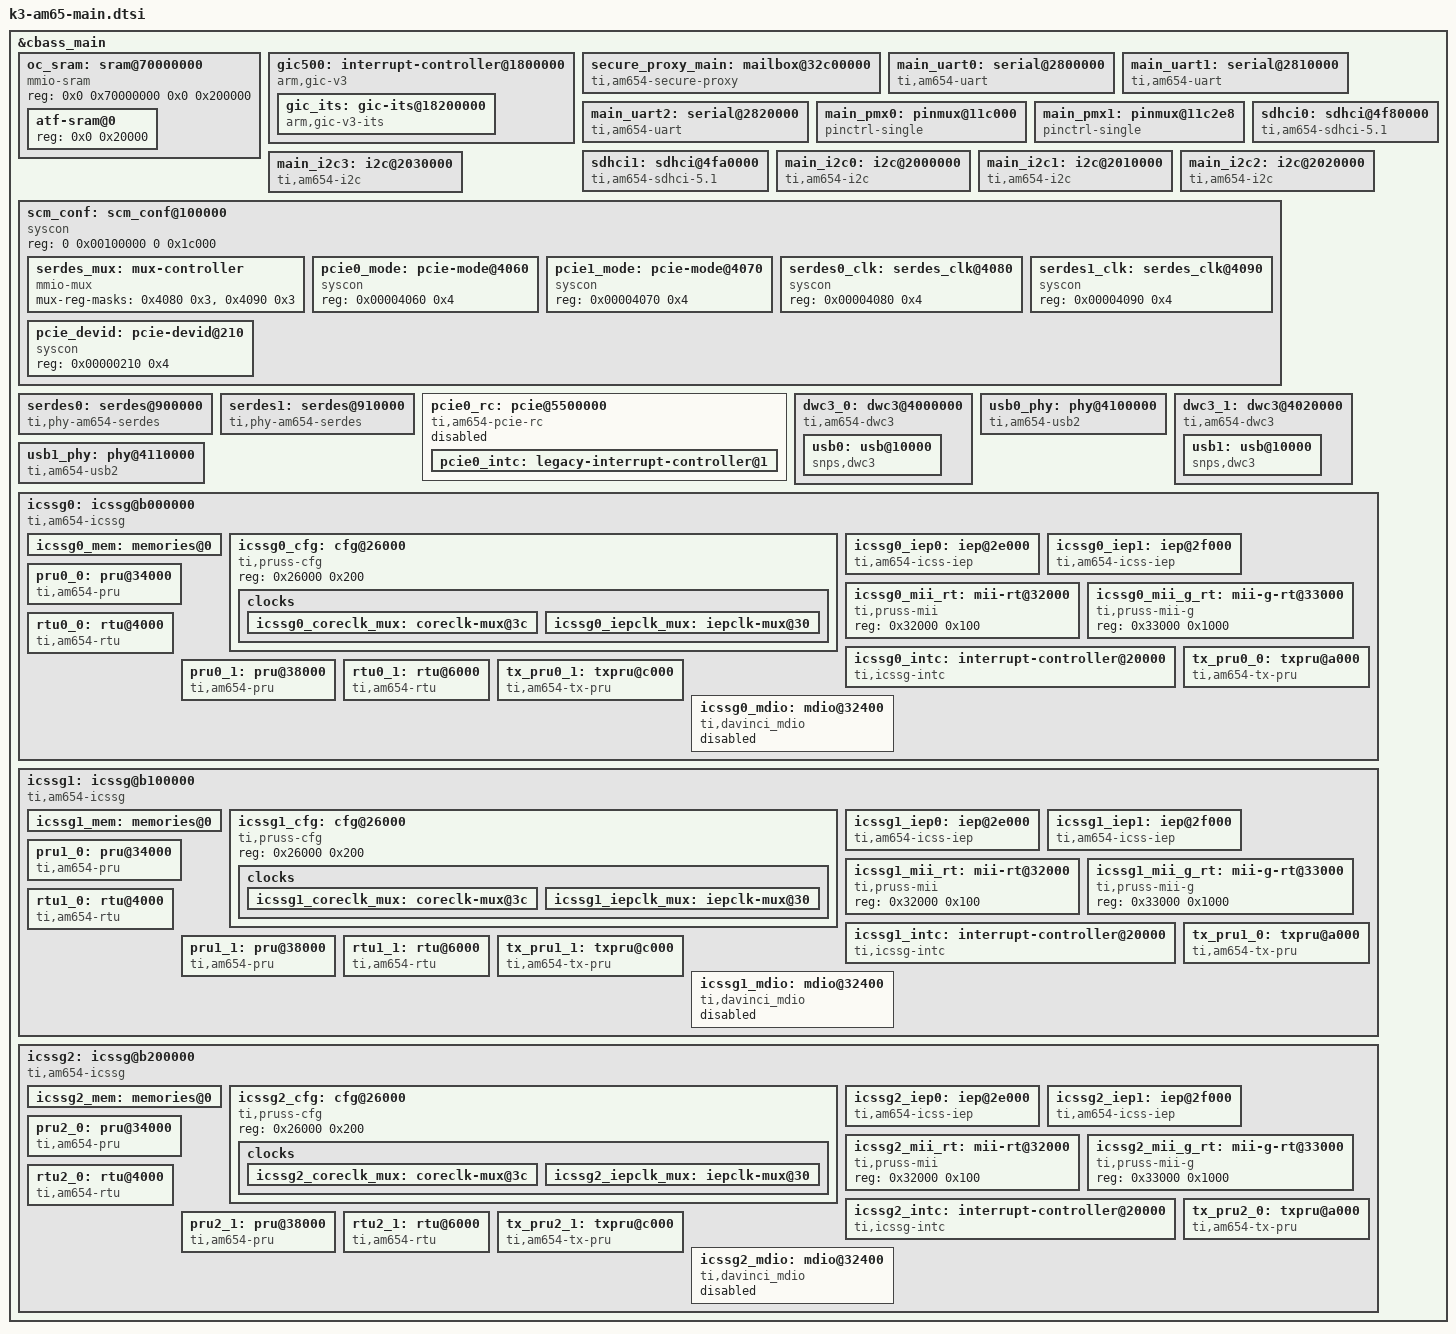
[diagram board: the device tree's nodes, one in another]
// SPDX-License-Identifier: GPL-2.0
/*
 * Device Tree Source for AM6 SoC Family Main Domain peripherals
 *
 * Copyright (C) 2016-2018 Texas Instruments Incorporated - http://www.ti.com/
 */

#include <dt-bindings/phy/phy-am654-serdes.h>
#include <dt-bindings/phy/phy.h>

&cbass_main {
	oc_sram: sram@70000000 {
		compatible = "mmio-sram";
		reg = <0x0 0x70000000 0x0 0x200000>;
		#address-cells = <1>;
		#size-cells = <1>;
		ranges = <0x0 0x0 0x70000000 0x200000>;

		atf-sram@0 {
			reg = <0x0 0x20000>;
		};
	};

	gic500: interrupt-controller@1800000 {
		compatible = "arm,gic-v3";
		#address-cells = <2>;
		#size-cells = <2>;
		ranges;
		#interrupt-cells = <3>;
		interrupt-controller;
		reg = <0x00 0x01800000 0x00 0x10000>,	/* GICD */
		      <0x00 0x01880000 0x00 0x90000>;	/* GICR */
		/*
		 * vcpumntirq:
		 * virtual CPU interface maintenance interrupt
		 */
		interrupts = <GIC_PPI 9 IRQ_TYPE_LEVEL_HIGH>;

		gic_its: gic-its@18200000 {
			compatible = "arm,gic-v3-its";
			reg = <0x00 0x01820000 0x00 0x10000>;
			msi-controller;
			#msi-cells = <1>;
		};
	};

	secure_proxy_main: mailbox@32c00000 {
		compatible = "ti,am654-secure-proxy";
		#mbox-cells = <1>;
		reg-names = "target_data", "rt", "scfg";
		reg = <0x00 0x32c00000 0x00 0x100000>,
		      <0x00 0x32400000 0x00 0x100000>,
		      <0x00 0x32800000 0x00 0x100000>;
		interrupt-names = "rx_011";
		interrupts = <GIC_SPI 37 IRQ_TYPE_LEVEL_HIGH>;
	};

	main_uart0: serial@2800000 {
		compatible = "ti,am654-uart";
		reg = <0x00 0x02800000 0x00 0x100>;
		reg-shift = <2>;
		reg-io-width = <4>;
		interrupts = <GIC_SPI 192 IRQ_TYPE_LEVEL_HIGH>;
		clock-frequency = <48000000>;
		current-speed = <115200>;
	};

	main_uart1: serial@2810000 {
		compatible = "ti,am654-uart";
		reg = <0x00 0x02810000 0x00 0x100>;
		reg-shift = <2>;
		reg-io-width = <4>;
		interrupts = <GIC_SPI 193 IRQ_TYPE_LEVEL_HIGH>;
		clock-frequency = <48000000>;
		current-speed = <115200>;
	};

	main_uart2: serial@2820000 {
		compatible = "ti,am654-uart";
		reg = <0x00 0x02820000 0x00 0x100>;
		reg-shift = <2>;
		reg-io-width = <4>;
		interrupts = <GIC_SPI 194 IRQ_TYPE_LEVEL_HIGH>;
		clock-frequency = <48000000>;
		current-speed = <115200>;
	};

	main_pmx0: pinmux@11c000 {
		compatible = "pinctrl-single";
		reg = <0x0 0x11c000 0x0 0x2e4>;
		#pinctrl-cells = <1>;
		pinctrl-single,register-width = <32>;
		pinctrl-single,function-mask = <0xffffffff>;
	};

	main_pmx1: pinmux@11c2e8 {
		compatible = "pinctrl-single";
		reg = <0x0 0x11c2e8 0x0 0x24>;
		#pinctrl-cells = <1>;
		pinctrl-single,register-width = <32>;
		pinctrl-single,function-mask = <0xffffffff>;
	};

	sdhci0: sdhci@4f80000 {
		compatible = "ti,am654-sdhci-5.1";
		reg = <0x0 0x4f80000 0x0 0x260>, <0x0 0x4f90000 0x0 0x134>;
		power-domains = <&k3_pds 47 TI_SCI_PD_EXCLUSIVE>;
		clocks = <&k3_clks 47 0>, <&k3_clks 47 1>;
		clock-names = "clk_ahb", "clk_xin";
		interrupts = <GIC_SPI 136 IRQ_TYPE_LEVEL_HIGH>;
		mmc-ddr-1_8v;
		mmc-hs200-1_8v;
		ti,otap-del-sel-legacy = <0x0>;
		ti,otap-del-sel-mmc-hs = <0x0>;
		ti,otap-del-sel-sd-hs = <0x0>;
		ti,otap-del-sel-sdr12 = <0x0>;
		ti,otap-del-sel-sdr25 = <0x0>;
		ti,otap-del-sel-sdr50 = <0x8>;
		ti,otap-del-sel-sdr104 = <0x5>;
		ti,otap-del-sel-ddr50 = <0x5>;
		ti,otap-del-sel-ddr52 = <0x5>;
		ti,otap-del-sel-hs200 = <0x5>;
		ti,otap-del-sel-hs400 = <0x0>;
		ti,itap-del-sel-legacy = <0xa>;
		ti,itap-del-sel-mmc-hs = <0x1>;
		ti,itap-del-sel-sdr12 = <0xa>;
		ti,itap-del-sel-sdr25 = <0x1>;
		ti,clkbuf-sel = <0x7>;
		ti,trm-icp = <0x8>;
		dma-coherent;
	};

	sdhci1: sdhci@4fa0000 {
		compatible = "ti,am654-sdhci-5.1";
		reg = <0x0 0x4fa0000 0x0 0x260>, <0x0 0x4fb0000 0x0 0x134>;
		power-domains = <&k3_pds 48 TI_SCI_PD_EXCLUSIVE>;
		clocks = <&k3_clks 48 0>, <&k3_clks 48 1>;
		clock-names = "clk_ahb", "clk_xin";
		interrupts = <GIC_SPI 137 IRQ_TYPE_LEVEL_HIGH>;
		ti,otap-del-sel-legacy = <0x0>;
		ti,otap-del-sel-mmc-hs = <0x0>;
		ti,otap-del-sel-sd-hs = <0x0>;
		ti,otap-del-sel-sdr12 = <0x0>;
		ti,otap-del-sel-sdr25 = <0x0>;
		ti,otap-del-sel-sdr50 = <0x8>;
		ti,otap-del-sel-sdr104 = <0x7>;
		ti,otap-del-sel-ddr50 = <0x4>;
		ti,otap-del-sel-ddr52 = <0x4>;
		ti,otap-del-sel-hs200 = <0x7>;
		ti,itap-del-sel-legacy = <0xa>;
		ti,itap-del-sel-mmc-hs = <0x1>;
		ti,itap-del-sel-sdr12 = <0xa>;
		ti,itap-del-sel-sdr25 = <0x1>;
		ti,clkbuf-sel = <0x7>;
		ti,trm-icp = <0x8>;
		dma-coherent;
	};

	main_i2c0: i2c@2000000 {
		compatible = "ti,am654-i2c", "ti,omap4-i2c";
		reg = <0x0 0x2000000 0x0 0x100>;
		interrupts = <GIC_SPI 200 IRQ_TYPE_LEVEL_HIGH>;
		#address-cells = <1>;
		#size-cells = <0>;
		clock-names = "fck";
		clocks = <&k3_clks 110 1>;
		power-domains = <&k3_pds 110 TI_SCI_PD_EXCLUSIVE>;
	};

	main_i2c1: i2c@2010000 {
		compatible = "ti,am654-i2c", "ti,omap4-i2c";
		reg = <0x0 0x2010000 0x0 0x100>;
		interrupts = <GIC_SPI 201 IRQ_TYPE_LEVEL_HIGH>;
		#address-cells = <1>;
		#size-cells = <0>;
		clock-names = "fck";
		clocks = <&k3_clks 111 1>;
		power-domains = <&k3_pds 111 TI_SCI_PD_EXCLUSIVE>;
	};

	main_i2c2: i2c@2020000 {
		compatible = "ti,am654-i2c", "ti,omap4-i2c";
		reg = <0x0 0x2020000 0x0 0x100>;
		interrupts = <GIC_SPI 202 IRQ_TYPE_LEVEL_HIGH>;
		#address-cells = <1>;
		#size-cells = <0>;
		clock-names = "fck";
		clocks = <&k3_clks 112 1>;
		power-domains = <&k3_pds 112 TI_SCI_PD_EXCLUSIVE>;
	};

	main_i2c3: i2c@2030000 {
		compatible = "ti,am654-i2c", "ti,omap4-i2c";
		reg = <0x0 0x2030000 0x0 0x100>;
		interrupts = <GIC_SPI 203 IRQ_TYPE_LEVEL_HIGH>;
		#address-cells = <1>;
		#size-cells = <0>;
		clock-names = "fck";
		clocks = <&k3_clks 113 1>;
		power-domains = <&k3_pds 113 TI_SCI_PD_EXCLUSIVE>;
	};

	scm_conf: scm_conf@100000 {
		compatible = "syscon", "simple-mfd";
		reg = <0 0x00100000 0 0x1c000>;
		#address-cells = <1>;
		#size-cells = <1>;
		ranges = <0x0 0x0 0x00100000 0x1c000>;

		serdes_mux: mux-controller {
			compatible = "mmio-mux";
			#mux-control-cells = <1>;
			mux-reg-masks = <0x4080 0x3>, /* SERDES0 lane select */
					<0x4090 0x3>; /* SERDES1 lane select */
		};

		pcie0_mode: pcie-mode@4060 {
			compatible = "syscon";
			reg = <0x00004060 0x4>;
		};

		pcie1_mode: pcie-mode@4070 {
			compatible = "syscon";
			reg = <0x00004070 0x4>;
		};

		serdes0_clk: serdes_clk@4080 {
			compatible = "syscon";
			reg = <0x00004080 0x4>;
		};

		serdes1_clk: serdes_clk@4090 {
			compatible = "syscon";
			reg = <0x00004090 0x4>;
		};

		pcie_devid: pcie-devid@210 {
			compatible = "syscon";
			reg = <0x00000210 0x4>;
		};
	};

	serdes0: serdes@900000 {
		compatible = "ti,phy-am654-serdes";
		reg = <0x0 0x900000 0x0 0x2000>;
		reg-names = "serdes";
		#phy-cells = <2>;
		power-domains = <&k3_pds 153 TI_SCI_PD_EXCLUSIVE>;
		clocks = <&k3_clks 153 4>, <&k3_clks 153 1>, <&serdes1 AM654_SERDES_LO_REFCLK>;
		clock-output-names = "serdes0_cmu_refclk", "serdes0_lo_refclk", "serdes0_ro_refclk";
		assigned-clocks = <&k3_clks 153 4>, <&serdes0 AM654_SERDES_CMU_REFCLK>;
		assigned-clock-parents = <&k3_clks 153 8>, <&k3_clks 153 4>;
		ti,serdes-clk = <&serdes0_clk>;
		mux-controls = <&serdes_mux 0>;
		#clock-cells = <1>;
	};

	serdes1: serdes@910000 {
		compatible = "ti,phy-am654-serdes";
		reg = <0x0 0x910000 0x0 0x2000>;
		reg-names = "serdes";
		#phy-cells = <2>;
		power-domains = <&k3_pds 154 TI_SCI_PD_EXCLUSIVE>;
		clocks = <&serdes0 AM654_SERDES_RO_REFCLK>, <&k3_clks 154 1>, <&k3_clks 154 5>;
		clock-output-names = "serdes1_cmu_refclk", "serdes1_lo_refclk", "serdes1_ro_refclk";
		assigned-clocks = <&k3_clks 154 5>, <&serdes1 AM654_SERDES_CMU_REFCLK>;
		assigned-clock-parents = <&k3_clks 154 9>, <&k3_clks 154 5>;
		ti,serdes-clk = <&serdes1_clk>;
		mux-controls = <&serdes_mux 1>;
		#clock-cells = <1>;
	};

	pcie0_rc: pcie@5500000 {
		compatible = "ti,am654-pcie-rc";
		reg =  <0x0 0x5500000 0x0 0x1000>, <0x0 0x5501000 0x0 0x1000>, <0x0 0x10000000 0x0 0x2000>, <0x0 0x5506000 0x0 0x1000>;
		reg-names = "app", "dbics", "config", "atu";
		power-domains = <&k3_pds 120 TI_SCI_PD_EXCLUSIVE>;
		#address-cells = <3>;
		#size-cells = <2>;
		ranges = <0x81000000 0 0          0x0   0x10020000 0 0x00010000
			  0x82000000 0 0x10030000 0x0   0x10030000 0 0x07FD0000>;
		ti,syscon-pcie-id = <&pcie_devid>;
		ti,syscon-pcie-mode = <&pcie0_mode>;
		bus-range = <0x0 0xff>;
		status = "disabled";
		device_type = "pci";
		num-lanes = <1>;
		num-ob-windows = <16>;
		num-viewport = <16>;
		max-link-speed = <3>;
		interrupts = <GIC_SPI 340 IRQ_TYPE_EDGE_RISING>;
		#interrupt-cells = <1>;
		interrupt-map-mask = <0 0 0 7>;
		interrupt-map = <0 0 0 1 &pcie0_intc 0>, /* INT A */
				<0 0 0 2 &pcie0_intc 0>, /* INT B */
				<0 0 0 3 &pcie0_intc 0>, /* INT C */
				<0 0 0 4 &pcie0_intc 0>; /* INT D */
		msi-map = <0x0 &gic_its 0x0 0x10000>;

		pcie0_intc: legacy-interrupt-controller@1 {
			interrupt-controller;
			#interrupt-cells = <1>;
			interrupt-parent = <&gic500>;
			interrupts = <GIC_SPI 328 IRQ_TYPE_EDGE_RISING>;
		};
	};

	dwc3_0: dwc3@4000000 {
		compatible = "ti,am654-dwc3";
		reg = <0x0 0x4000000 0x0 0x4000>;
		#address-cells = <1>;
		#size-cells = <1>;
		ranges = <0x0 0x0 0x4000000 0x20000>;
		interrupts = <GIC_SPI 97 IRQ_TYPE_LEVEL_HIGH>;
		dma-coherent;
		power-domains = <&k3_pds 151 TI_SCI_PD_EXCLUSIVE>;
		assigned-clocks = <&k3_clks 151 2>, <&k3_clks 151 7>;
		assigned-clock-parents = <&k3_clks 151 4>,	/* set REF_CLK to 20MHz i.e. PER0_PLL/48 */
					 <&k3_clks 151 9>;	/* set PIPE3_TXB_CLK to CLK_12M_RC/256 (for HS only) */

		usb0: usb@10000 {
			compatible = "snps,dwc3";
			reg = <0x10000 0x10000>;
			interrupts = <GIC_SPI 100 IRQ_TYPE_LEVEL_HIGH>,
				     <GIC_SPI 100 IRQ_TYPE_LEVEL_HIGH>,
				     <GIC_SPI 96 IRQ_TYPE_LEVEL_HIGH>;
			interrupt-names = "peripheral",
					  "host",
					  "otg";
			maximum-speed = "high-speed";
			dr_mode = "otg";
			phys = <&usb0_phy>;
			phy-names = "usb2-phy";
			snps,dis_u3_susphy_quirk;
		};
	};

	usb0_phy: phy@4100000 {
		compatible = "ti,am654-usb2", "ti,omap-usb2";
		reg = <0x0 0x4100000 0x0 0x54>;
		syscon-phy-power = <&scm_conf 0x4000>;
		clocks = <&k3_clks 151 0>, <&k3_clks 151 1>;
		clock-names = "wkupclk", "refclk";
		#phy-cells = <0>;
		ti,dis-chg-det-quirk;
	};

	dwc3_1: dwc3@4020000 {
		compatible = "ti,am654-dwc3";
		reg = <0x0 0x4020000 0x0 0x4000>;
		#address-cells = <1>;
		#size-cells = <1>;
		ranges = <0x0 0x0 0x4020000 0x20000>;
		interrupts = <GIC_SPI 117 IRQ_TYPE_LEVEL_HIGH>;
		dma-coherent;
		power-domains = <&k3_pds 152 TI_SCI_PD_EXCLUSIVE>;
		assigned-clocks = <&k3_clks 152 2>;
		assigned-clock-parents = <&k3_clks 152 4>;	/* set REF_CLK to 20MHz i.e. PER0_PLL/48 */

		usb1: usb@10000 {
			compatible = "snps,dwc3";
			reg = <0x10000 0x10000>;
			interrupts = <GIC_SPI 120 IRQ_TYPE_LEVEL_HIGH>,
				     <GIC_SPI 120 IRQ_TYPE_LEVEL_HIGH>,
				     <GIC_SPI 116 IRQ_TYPE_LEVEL_HIGH>;
			interrupt-names = "peripheral",
					  "host",
					  "otg";
			maximum-speed = "high-speed";
			dr_mode = "otg";
			phys = <&usb1_phy>;
			phy-names = "usb2-phy";
		};
	};

	usb1_phy: phy@4110000 {
		compatible = "ti,am654-usb2", "ti,omap-usb2";
		reg = <0x0 0x4110000 0x0 0x54>;
		syscon-phy-power = <&scm_conf 0x4020>;
		clocks = <&k3_clks 152 0>, <&k3_clks 152 1>;
		clock-names = "wkupclk", "refclk";
		#phy-cells = <0>;
		ti,dis-chg-det-quirk;
	};

	icssg0: icssg@b000000 {
		compatible = "ti,am654-icssg";
		reg = <0x00 0xb000000 0x00 0x80000>;
		power-domains = <&k3_pds 62 TI_SCI_PD_EXCLUSIVE>;
		#address-cells = <1>;
		#size-cells = <1>;
		ranges = <0x0 0x00 0xb000000 0x80000>;

		icssg0_mem: memories@0 {
			reg = <0x0 0x2000>,
			      <0x2000 0x2000>,
			      <0x10000 0x10000>;
			reg-names = "dram0", "dram1",
				    "shrdram2";
		};

		icssg0_cfg: cfg@26000 {
			compatible = "ti,pruss-cfg", "syscon";
			reg = <0x26000 0x200>;
			#address-cells = <1>;
			#size-cells = <1>;
			ranges = <0x0 0x26000 0x2000>;

			clocks {
				#address-cells = <1>;
				#size-cells = <0>;

				icssg0_coreclk_mux: coreclk-mux@3c {
					reg = <0x3c>;
					#clock-cells = <0>;
					clocks = <&k3_clks 62 19>, /* icssg0_core_clk */
						 <&k3_clks 62 3>;  /* icssg0_iclk */
					assigned-clocks = <&icssg0_coreclk_mux>;
					assigned-clock-parents = <&k3_clks 62 3>;
				};

				icssg0_iepclk_mux: iepclk-mux@30 {
					reg = <0x30>;
					#clock-cells = <0>;
					clocks = <&k3_clks 62 10>,	/* icssg0_iep_clk */
						 <&icssg0_coreclk_mux>;	/* core_clk */
					assigned-clocks = <&icssg0_iepclk_mux>;
					assigned-clock-parents = <&icssg0_coreclk_mux>;
				};
			};
		};

		icssg0_iep0: iep@2e000 {
			compatible = "ti,am654-icss-iep";
			reg = <0x2e000 0x1000>;
			clocks = <&icssg0_iepclk_mux>;
		};

		icssg0_iep1: iep@2f000 {
			compatible = "ti,am654-icss-iep";
			reg = <0x2f000 0x1000>;
			clocks = <&icssg0_iepclk_mux>;
		};

		icssg0_mii_rt: mii-rt@32000 {
			compatible = "ti,pruss-mii", "syscon";
			reg = <0x32000 0x100>;
		};

		icssg0_mii_g_rt: mii-g-rt@33000 {
			compatible = "ti,pruss-mii-g", "syscon";
			reg = <0x33000 0x1000>;
		};

		icssg0_intc: interrupt-controller@20000 {
			compatible = "ti,icssg-intc";
			reg = <0x20000 0x2000>;
			interrupt-controller;
			#interrupt-cells = <3>;
			interrupts = <GIC_SPI 254 IRQ_TYPE_LEVEL_HIGH>,
				     <GIC_SPI 255 IRQ_TYPE_LEVEL_HIGH>,
				     <GIC_SPI 256 IRQ_TYPE_LEVEL_HIGH>,
				     <GIC_SPI 257 IRQ_TYPE_LEVEL_HIGH>,
				     <GIC_SPI 258 IRQ_TYPE_LEVEL_HIGH>,
				     <GIC_SPI 259 IRQ_TYPE_LEVEL_HIGH>,
				     <GIC_SPI 260 IRQ_TYPE_LEVEL_HIGH>,
				     <GIC_SPI 261 IRQ_TYPE_LEVEL_HIGH>;
			interrupt-names = "host_intr0", "host_intr1",
					  "host_intr2", "host_intr3",
					  "host_intr4", "host_intr5",
					  "host_intr6", "host_intr7";
		};

		pru0_0: pru@34000 {
			compatible = "ti,am654-pru";
			reg = <0x34000 0x4000>,
			      <0x22000 0x100>,
			      <0x22400 0x100>;
			reg-names = "iram", "control", "debug";
			firmware-name = "am65x-pru0_0-fw";
		};

		rtu0_0: rtu@4000 {
			compatible = "ti,am654-rtu";
			reg = <0x4000 0x2000>,
			      <0x23000 0x100>,
			      <0x23400 0x100>;
			reg-names = "iram", "control", "debug";
			firmware-name = "am65x-rtu0_0-fw";
		};

		tx_pru0_0: txpru@a000 {
			compatible = "ti,am654-tx-pru";
			reg = <0xa000 0x1800>,
			      <0x25000 0x100>,
			      <0x25400 0x100>;
			reg-names = "iram", "control", "debug";
			firmware-name = "am65x-txpru0_0-fw";
		};

		pru0_1: pru@38000 {
			compatible = "ti,am654-pru";
			reg = <0x38000 0x4000>,
			      <0x24000 0x100>,
			      <0x24400 0x100>;
			reg-names = "iram", "control", "debug";
			firmware-name = "am65x-pru0_1-fw";
		};

		rtu0_1: rtu@6000 {
			compatible = "ti,am654-rtu";
			reg = <0x6000 0x2000>,
			      <0x23800 0x100>,
			      <0x23c00 0x100>;
			reg-names = "iram", "control", "debug";
			firmware-name = "am65x-rtu0_1-fw";
		};

		tx_pru0_1: txpru@c000 {
			compatible = "ti,am654-tx-pru";
			reg = <0xc000 0x1800>,
			      <0x25800 0x100>,
			      <0x25c00 0x100>;
			reg-names = "iram", "control", "debug";
			firmware-name = "am65x-txpru0_1-fw";
		};

		icssg0_mdio: mdio@32400 {
			compatible = "ti,davinci_mdio";
			reg = <0x32400 0x100>;
			clocks = <&k3_clks 62 3>;
			clock-names = "fck";
			#address-cells = <1>;
			#size-cells = <0>;
			bus_freq = <1000000>;
			status = "disabled";
		};
	};

	icssg1: icssg@b100000 {
		compatible = "ti,am654-icssg";
		reg = <0x00 0xb100000 0x00 0x80000>;
		power-domains = <&k3_pds 63 TI_SCI_PD_EXCLUSIVE>;
		#address-cells = <1>;
		#size-cells = <1>;
		ranges = <0x0 0x00 0xb100000 0x80000>;

		icssg1_mem: memories@0 {
			reg = <0x0 0x2000>,
			      <0x2000 0x2000>,
			      <0x10000 0x10000>;
			reg-names = "dram0", "dram1",
				    "shrdram2";
		};

		icssg1_cfg: cfg@26000 {
			compatible = "ti,pruss-cfg", "syscon";
			reg = <0x26000 0x200>;
			#address-cells = <1>;
			#size-cells = <1>;
			ranges = <0x0 0x26000 0x2000>;

			clocks {
				#address-cells = <1>;
				#size-cells = <0>;

				icssg1_coreclk_mux: coreclk-mux@3c {
					reg = <0x3c>;
					#clock-cells = <0>;
					clocks = <&k3_clks 63 19>, /* icssg1_core_clk */
						 <&k3_clks 63 3>;  /* icssg1_iclk */
					assigned-clocks = <&icssg1_coreclk_mux>;
					assigned-clock-parents = <&k3_clks 63 3>;
				};

				icssg1_iepclk_mux: iepclk-mux@30 {
					reg = <0x30>;
					#clock-cells = <0>;
					clocks = <&k3_clks 63 10>,	/* icssg1_iep_clk */
						 <&icssg1_coreclk_mux>;	/* core_clk */
					assigned-clocks = <&icssg1_iepclk_mux>;
					assigned-clock-parents = <&icssg1_coreclk_mux>;
				};
			};
		};

		icssg1_iep0: iep@2e000 {
			compatible = "ti,am654-icss-iep";
			reg = <0x2e000 0x1000>;
			clocks = <&icssg1_iepclk_mux>;
		};

		icssg1_iep1: iep@2f000 {
			compatible = "ti,am654-icss-iep";
			reg = <0x2f000 0x1000>;
			clocks = <&icssg1_iepclk_mux>;
		};

		icssg1_mii_rt: mii-rt@32000 {
			compatible = "ti,pruss-mii", "syscon";
			reg = <0x32000 0x100>;
		};

		icssg1_mii_g_rt: mii-g-rt@33000 {
			compatible = "ti,pruss-mii-g", "syscon";
			reg = <0x33000 0x1000>;
		};

		icssg1_intc: interrupt-controller@20000 {
			compatible = "ti,icssg-intc";
			reg = <0x20000 0x2000>;
			interrupt-controller;
			#interrupt-cells = <3>;
			interrupts = <GIC_SPI 262 IRQ_TYPE_LEVEL_HIGH>,
				     <GIC_SPI 263 IRQ_TYPE_LEVEL_HIGH>,
				     <GIC_SPI 264 IRQ_TYPE_LEVEL_HIGH>,
				     <GIC_SPI 265 IRQ_TYPE_LEVEL_HIGH>,
				     <GIC_SPI 266 IRQ_TYPE_LEVEL_HIGH>,
				     <GIC_SPI 267 IRQ_TYPE_LEVEL_HIGH>,
				     <GIC_SPI 268 IRQ_TYPE_LEVEL_HIGH>,
				     <GIC_SPI 269 IRQ_TYPE_LEVEL_HIGH>;
			interrupt-names = "host_intr0", "host_intr1",
					  "host_intr2", "host_intr3",
					  "host_intr4", "host_intr5",
					  "host_intr6", "host_intr7";
		};

		pru1_0: pru@34000 {
			compatible = "ti,am654-pru";
			reg = <0x34000 0x4000>,
			      <0x22000 0x100>,
			      <0x22400 0x100>;
			reg-names = "iram", "control", "debug";
			firmware-name = "am65x-pru1_0-fw";
		};

		rtu1_0: rtu@4000 {
			compatible = "ti,am654-rtu";
			reg = <0x4000 0x2000>,
			      <0x23000 0x100>,
			      <0x23400 0x100>;
			reg-names = "iram", "control", "debug";
			firmware-name = "am65x-rtu1_0-fw";
		};

		tx_pru1_0: txpru@a000 {
			compatible = "ti,am654-tx-pru";
			reg = <0xa000 0x1800>,
			      <0x25000 0x100>,
			      <0x25400 0x100>;
			reg-names = "iram", "control", "debug";
			firmware-name = "am65x-txpru1_0-fw";
		};

		pru1_1: pru@38000 {
			compatible = "ti,am654-pru";
			reg = <0x38000 0x4000>,
			      <0x24000 0x100>,
			      <0x24400 0x100>;
			reg-names = "iram", "control", "debug";
			firmware-name = "am65x-pru1_1-fw";
		};

		rtu1_1: rtu@6000 {
			compatible = "ti,am654-rtu";
			reg = <0x6000 0x2000>,
			      <0x23800 0x100>,
			      <0x23c00 0x100>;
			reg-names = "iram", "control", "debug";
			firmware-name = "am65x-rtu1_1-fw";
		};

		tx_pru1_1: txpru@c000 {
			compatible = "ti,am654-tx-pru";
			reg = <0xc000 0x1800>,
			      <0x25800 0x100>,
			      <0x25c00 0x100>;
			reg-names = "iram", "control", "debug";
			firmware-name = "am65x-txpru1_1-fw";
		};

		icssg1_mdio: mdio@32400 {
			compatible = "ti,davinci_mdio";
			reg = <0x32400 0x100>;
			clocks = <&k3_clks 63 3>;
			clock-names = "fck";
			#address-cells = <1>;
			#size-cells = <0>;
			bus_freq = <1000000>;
			status = "disabled";
		};
	};

	icssg2: icssg@b200000 {
		compatible = "ti,am654-icssg";
		reg = <0x00 0xb200000 0x00 0x80000>;
		power-domains = <&k3_pds 64 TI_SCI_PD_EXCLUSIVE>;
		#address-cells = <1>;
		#size-cells = <1>;
		ranges = <0x0 0x00 0xb200000 0x80000>;

		icssg2_mem: memories@0 {
			reg = <0x0 0x2000>,
			      <0x2000 0x2000>,
			      <0x10000 0x10000>;
			reg-names = "dram0", "dram1",
				    "shrdram2";
		};

		icssg2_cfg: cfg@26000 {
			compatible = "ti,pruss-cfg", "syscon";
			reg = <0x26000 0x200>;
			#address-cells = <1>;
			#size-cells = <1>;
			ranges = <0x0 0x26000 0x2000>;

			clocks {
				#address-cells = <1>;
				#size-cells = <0>;

				icssg2_coreclk_mux: coreclk-mux@3c {
					reg = <0x3c>;
					#clock-cells = <0>;
					clocks = <&k3_clks 64 19>, /* icssg1_core_clk */
						 <&k3_clks 64 3>;  /* icssg1_iclk */
					assigned-clocks = <&icssg2_coreclk_mux>;
					assigned-clock-parents = <&k3_clks 64 3>;
				};

				icssg2_iepclk_mux: iepclk-mux@30 {
					reg = <0x30>;
					#clock-cells = <0>;
					clocks = <&k3_clks 64 10>,	/* icssg1_iep_clk */
						 <&icssg2_coreclk_mux>;	/* core_clk */
					assigned-clocks = <&icssg2_iepclk_mux>;
					assigned-clock-parents = <&icssg2_coreclk_mux>;
				};
			};
		};

		icssg2_iep0: iep@2e000 {
			compatible = "ti,am654-icss-iep";
			reg = <0x2e000 0x1000>;
			clocks = <&icssg2_iepclk_mux>;
		};

		icssg2_iep1: iep@2f000 {
			compatible = "ti,am654-icss-iep";
			reg = <0x2f000 0x1000>;
			clocks = <&icssg2_iepclk_mux>;
		};

		icssg2_mii_rt: mii-rt@32000 {
			compatible = "ti,pruss-mii", "syscon";
			reg = <0x32000 0x100>;
		};

		icssg2_mii_g_rt: mii-g-rt@33000 {
			compatible = "ti,pruss-mii-g", "syscon";
			reg = <0x33000 0x1000>;
		};

		icssg2_intc: interrupt-controller@20000 {
			compatible = "ti,icssg-intc";
			reg = <0x20000 0x2000>;
			interrupt-controller;
			#interrupt-cells = <3>;
			interrupts = <GIC_SPI 270 IRQ_TYPE_LEVEL_HIGH>,
				     <GIC_SPI 271 IRQ_TYPE_LEVEL_HIGH>,
				     <GIC_SPI 272 IRQ_TYPE_LEVEL_HIGH>,
				     <GIC_SPI 273 IRQ_TYPE_LEVEL_HIGH>,
				     <GIC_SPI 274 IRQ_TYPE_LEVEL_HIGH>,
				     <GIC_SPI 275 IRQ_TYPE_LEVEL_HIGH>,
				     <GIC_SPI 276 IRQ_TYPE_LEVEL_HIGH>,
				     <GIC_SPI 277 IRQ_TYPE_LEVEL_HIGH>;
			interrupt-names = "host_intr0", "host_intr1",
					  "host_intr2", "host_intr3",
					  "host_intr4", "host_intr5",
					  "host_intr6", "host_intr7";
		};

		pru2_0: pru@34000 {
			compatible = "ti,am654-pru";
			reg = <0x34000 0x4000>,
			      <0x22000 0x100>,
			      <0x22400 0x100>;
			reg-names = "iram", "control", "debug";
			firmware-name = "am65x-pru2_0-fw";
		};

		rtu2_0: rtu@4000 {
			compatible = "ti,am654-rtu";
			reg = <0x4000 0x2000>,
			      <0x23000 0x100>,
			      <0x23400 0x100>;
			reg-names = "iram", "control", "debug";
			firmware-name = "am65x-rtu2_0-fw";
		};

		tx_pru2_0: txpru@a000 {
			compatible = "ti,am654-tx-pru";
			reg = <0xa000 0x1800>,
			      <0x25000 0x100>,
			      <0x25400 0x100>;
			reg-names = "iram", "control", "debug";
			firmware-name = "am65x-txpru2_0-fw";
		};

		pru2_1: pru@38000 {
			compatible = "ti,am654-pru";
			reg = <0x38000 0x4000>,
			      <0x24000 0x100>,
			      <0x24400 0x100>;
			reg-names = "iram", "control", "debug";
			firmware-name = "am65x-pru2_1-fw";
		};

		rtu2_1: rtu@6000 {
			compatible = "ti,am654-rtu";
			reg = <0x6000 0x2000>,
			      <0x23800 0x100>,
			      <0x23c00 0x100>;
			reg-names = "iram", "control", "debug";
			firmware-name = "am65x-rtu2_1-fw";
		};

		tx_pru2_1: txpru@c000 {
			compatible = "ti,am654-tx-pru";
			reg = <0xc000 0x1800>,
			      <0x25800 0x100>,
			      <0x25c00 0x100>;
			reg-names = "iram", "control", "debug";
			firmware-name = "am65x-txpru2_1-fw";
		};

		icssg2_mdio: mdio@32400 {
			compatible = "ti,davinci_mdio";
			reg = <0x32400 0x100>;
			clocks = <&k3_clks 64 3>;
			clock-names = "fck";
			#address-cells = <1>;
			#size-cells = <0>;
			bus_freq = <1000000>;
			status = "disabled";
		};
	};

};
